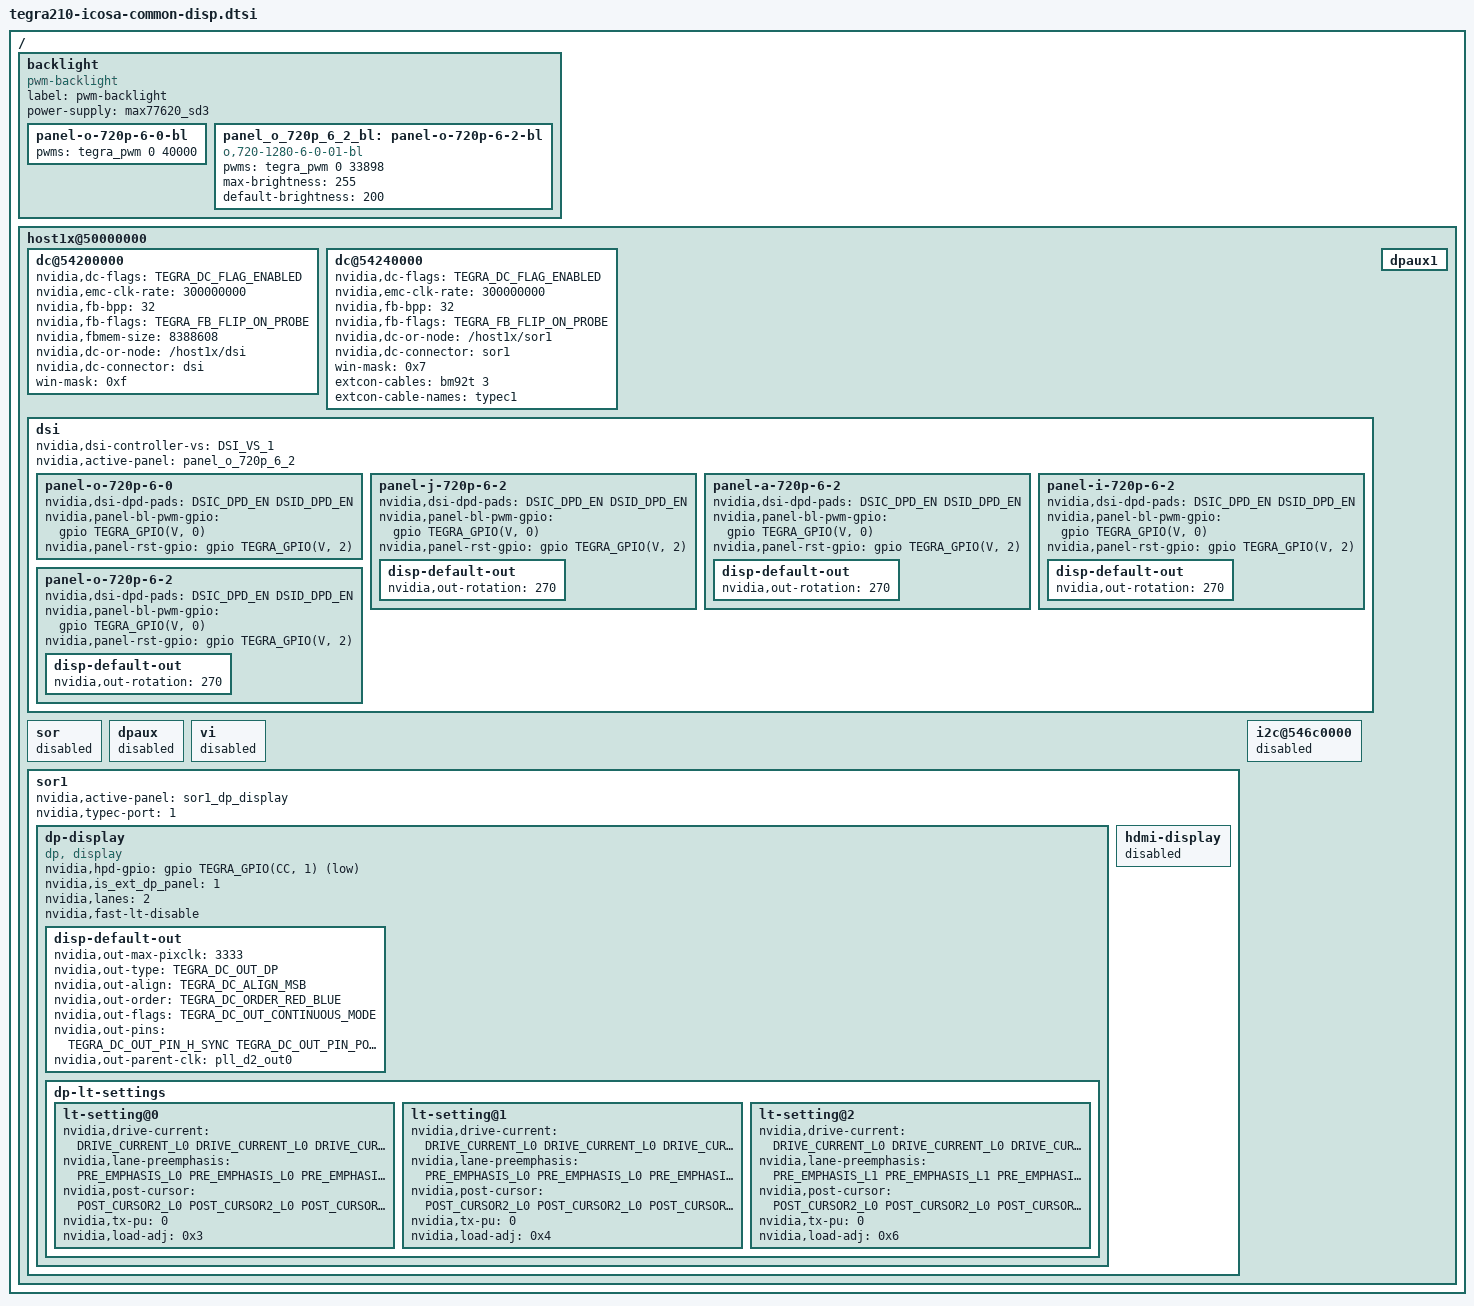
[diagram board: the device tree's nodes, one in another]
/*
 * arch/arm64/boot/dts/tegra210-icosa-common-disp.dtsi
 *
 * Copyright (c) 2016-2017, NVIDIA CORPORATION.  All rights reserved.
 * Copyright (c) 2020, CTCaer <ctcaer@gmail.com>
 *
 * This program is free software; you can redistribute it and/or modify
 * it under the terms of the GNU General Public License as published by
 * the Free Software Foundation; version 2 of the License.
 *
 * This program is distributed in the hope that it will be useful, but WITHOUT
 * ANY WARRANTY; without even the implied warranty of MERCHANTABILITY or
 * FITNESS FOR A PARTICULAR PURPOSE.  See the GNU General Public License for
 * more details.
 *
 */

#include <panels/panel-o-720p-6-0.dtsi>
#include "icosa-panels/panel-j-720p-6-2.dtsi"
#include "icosa-panels/panel-a-720p-6-2.dtsi"
#include "icosa-panels/panel-i-720p-6-2.dtsi"
#include "icosa-panels/panel-o-720p-6-2.dtsi"

/ {
	backlight {
		compatible = "pwm-backlight";
		status = "okay";
		label = "pwm-backlight";
		power-supply = <&max77620_sd3>;
		panel-o-720p-6-0-bl {
			pwms = <&tegra_pwm 0 40000>;
		};
		panel_o_720p_6_2_bl: panel-o-720p-6-2-bl {
			status = "okay";
			compatible = "o,720-1280-6-0-01-bl"; /* Compatible id must not change! */
			pwms = <&tegra_pwm 0 33898>;
			max-brightness = <255>;
			default-brightness = <200>;
		};
	};

	host1x@50000000 {
		/* tegradc.0 */
		dc@54200000 {
			status = "okay";
			nvidia,dc-flags = <TEGRA_DC_FLAG_ENABLED>;
			nvidia,emc-clk-rate = <300000000>;
			nvidia,fb-bpp = <32>; /* bits per pixel */
			nvidia,fb-flags = <TEGRA_FB_FLIP_ON_PROBE>;
			nvidia,fbmem-size = <8388608>; /* 8MB: double buffered panning 720x1280 */
			nvidia,dc-or-node = "/host1x/dsi";
			nvidia,dc-connector = <&dsi>;
			win-mask = <0xf>; /* Use all supported windows (Window A/B/C/D) for Android */
		};

		/* tegradc.1 */
		dc@54240000 {
			status = "okay"; /* Disable to enable built-in display fbcon */
			nvidia,dc-flags = <TEGRA_DC_FLAG_ENABLED>;
			nvidia,emc-clk-rate = <300000000>;
			nvidia,fb-bpp = <32>; /* bits per pixel */
			nvidia,fb-flags = <TEGRA_FB_FLIP_ON_PROBE>;
			nvidia,dc-or-node = "/host1x/sor1";
			nvidia,dc-connector = <&sor1>;
			win-mask = <0x7>; /* Use all supported windows (Window A/B/C) */
			extcon-cables = <&bm92t 3>;
			extcon-cable-names = "typec1";
			#extcon-cells = <1>;
		};

		dsi {
			nvidia,dsi-controller-vs = <DSI_VS_1>;
			status = "okay";
			nvidia,active-panel = <&panel_o_720p_6_2>;
			panel-o-720p-6-0 {
				nvidia,dsi-dpd-pads = <DSIC_DPD_EN DSID_DPD_EN>;
				nvidia,panel-bl-pwm-gpio = <&gpio TEGRA_GPIO(V, 0) 0>; /* PV0 */
				/* nvidia,panel-bl-en-gpio = <&gpio TEGRA_GPIO(V, 1) 0>; */ /* PV1. - Handled by vdd_lcd_bl_en-supply */
				nvidia,panel-rst-gpio = <&gpio TEGRA_GPIO(V, 2) 0>; /* PV2 */
			};
			panel-j-720p-6-2 {
				status = "okay";
				nvidia,dsi-dpd-pads = <DSIC_DPD_EN DSID_DPD_EN>;
				nvidia,panel-bl-pwm-gpio = <&gpio TEGRA_GPIO(V, 0) 0>; /* PV0 */
				/* nvidia,panel-bl-en-gpio = <&gpio TEGRA_GPIO(V, 1) 0>; */ /* PV1. - Handled by vdd_lcd_bl_en-supply */
				nvidia,panel-rst-gpio = <&gpio TEGRA_GPIO(V, 2) 0>; /* PV2 */
				disp-default-out {
					nvidia,out-rotation = <270>;
				};
			};
			panel-a-720p-6-2 {
				status = "okay";
				nvidia,dsi-dpd-pads = <DSIC_DPD_EN DSID_DPD_EN>;
				nvidia,panel-bl-pwm-gpio = <&gpio TEGRA_GPIO(V, 0) 0>; /* PV0 */
				/* nvidia,panel-bl-en-gpio = <&gpio TEGRA_GPIO(V, 1) 0>; */ /* PV1. - Handled by vdd_lcd_bl_en-supply */
				nvidia,panel-rst-gpio = <&gpio TEGRA_GPIO(V, 2) 0>; /* PV2 */
				disp-default-out {
					nvidia,out-rotation = <270>;
				};
			};
			panel-i-720p-6-2 {
				status = "okay";
				nvidia,dsi-dpd-pads = <DSIC_DPD_EN DSID_DPD_EN>;
				nvidia,panel-bl-pwm-gpio = <&gpio TEGRA_GPIO(V, 0) 0>; /* PV0 */
				/* nvidia,panel-bl-en-gpio = <&gpio TEGRA_GPIO(V, 1) 0>; */ /* PV1. - Handled by vdd_lcd_bl_en-supply */
				nvidia,panel-rst-gpio = <&gpio TEGRA_GPIO(V, 2) 0>; /* PV2 */
				disp-default-out {
					nvidia,out-rotation = <270>;
				};
			};
			panel-o-720p-6-2 {
				status = "okay";
				nvidia,dsi-dpd-pads = <DSIC_DPD_EN DSID_DPD_EN>;
				nvidia,panel-bl-pwm-gpio = <&gpio TEGRA_GPIO(V, 0) 0>; /* PV0 */
				/* nvidia,panel-bl-en-gpio = <&gpio TEGRA_GPIO(V, 1) 0>; */ /* PV1. - Handled by vdd_lcd_bl_en-supply */
				nvidia,panel-rst-gpio = <&gpio TEGRA_GPIO(V, 2) 0>; /* PV2 */
				disp-default-out {
					nvidia,out-rotation = <270>;
				};
			};
		};

		sor {
			status = "disabled";
		};

		dpaux {
			status = "disabled";
		};

		vi {
			status = "disabled";
		};

		sor1 {
			status = "okay";
			nvidia,active-panel = <&sor1_dp_display>;
			nvidia,typec-port = /bits/ 8 <1>;
			dp-display {
				status = "okay";
				compatible = "dp, display";
				nvidia,hpd-gpio = <&gpio TEGRA_GPIO(CC, 1) 1>; /* PN7 */
				nvidia,is_ext_dp_panel = <1>;
				nvidia,lanes = <2>;
				nvidia,fast-lt-disable;
				disp-default-out {
					nvidia,out-max-pixclk = <3333>; /* KHZ2PICOS(300000) */
					nvidia,out-type = <TEGRA_DC_OUT_DP>;
					nvidia,out-align = <TEGRA_DC_ALIGN_MSB>;
					nvidia,out-order = <TEGRA_DC_ORDER_RED_BLUE>;
					nvidia,out-flags = <TEGRA_DC_OUT_CONTINUOUS_MODE>;
					nvidia,out-pins = <TEGRA_DC_OUT_PIN_H_SYNC TEGRA_DC_OUT_PIN_POL_LOW
							   TEGRA_DC_OUT_PIN_V_SYNC TEGRA_DC_OUT_PIN_POL_LOW
							   TEGRA_DC_OUT_PIN_PIXEL_CLOCK TEGRA_DC_OUT_PIN_POL_LOW
							   TEGRA_DC_OUT_PIN_DATA_ENABLE TEGRA_DC_OUT_PIN_POL_HIGH>;
					nvidia,out-parent-clk = "pll_d2_out0";
				};
				dp-lt-settings {
					lt-setting@0 {
						nvidia,drive-current = <DRIVE_CURRENT_L0 DRIVE_CURRENT_L0 DRIVE_CURRENT_L0 DRIVE_CURRENT_L0>;
						nvidia,lane-preemphasis = <PRE_EMPHASIS_L0 PRE_EMPHASIS_L0 PRE_EMPHASIS_L0 PRE_EMPHASIS_L0>;
						nvidia,post-cursor = <POST_CURSOR2_L0 POST_CURSOR2_L0 POST_CURSOR2_L0 POST_CURSOR2_L0>;
						nvidia,tx-pu = <0>;
						nvidia,load-adj = <0x3>;
					};
					lt-setting@1 {
						nvidia,drive-current = <DRIVE_CURRENT_L0 DRIVE_CURRENT_L0 DRIVE_CURRENT_L0 DRIVE_CURRENT_L0>;
						nvidia,lane-preemphasis = <PRE_EMPHASIS_L0 PRE_EMPHASIS_L0 PRE_EMPHASIS_L0 PRE_EMPHASIS_L0>;
						nvidia,post-cursor = <POST_CURSOR2_L0 POST_CURSOR2_L0 POST_CURSOR2_L0 POST_CURSOR2_L0>;
						nvidia,tx-pu = <0>;
						nvidia,load-adj = <0x4>;
					};
					lt-setting@2 {
						nvidia,drive-current = <DRIVE_CURRENT_L0 DRIVE_CURRENT_L0 DRIVE_CURRENT_L0 DRIVE_CURRENT_L0>;
						nvidia,lane-preemphasis = <PRE_EMPHASIS_L1 PRE_EMPHASIS_L1 PRE_EMPHASIS_L1 PRE_EMPHASIS_L1>;
						nvidia,post-cursor = <POST_CURSOR2_L0 POST_CURSOR2_L0 POST_CURSOR2_L0 POST_CURSOR2_L0>;
						nvidia,tx-pu = <0>;
						nvidia,load-adj = <0x6>;
					};
				};
			};
			hdmi-display {
				status = "disabled";
			};
		};

		dpaux1 {
			status = "okay";
		};

		i2c@546c0000 {
			status = "disabled";
		};
	};
};
